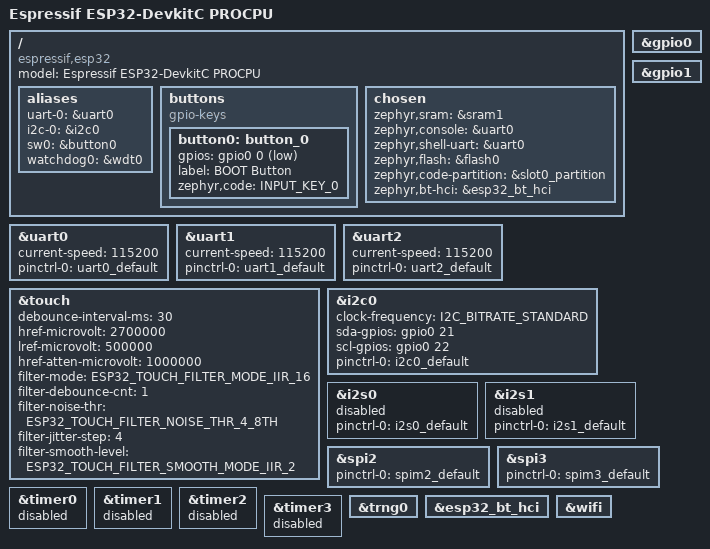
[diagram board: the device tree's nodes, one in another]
/*
 * Copyright (c) 2023-2025 Espressif Systems (Shanghai) Co., Ltd.
 *
 * SPDX-License-Identifier: Apache-2.0
 */
/dts-v1/;

#include <espressif/esp32/esp32_wrover_e_n4r8.dtsi>
#include "esp32_devkitc-pinctrl.dtsi"
#include <zephyr/dt-bindings/input/input-event-codes.h>
#include <zephyr/dt-bindings/input/esp32-touch-sensor-input.h>
#include <espressif/partitions_0x1000_amp.dtsi>

/ {
	model = "Espressif ESP32-DevkitC PROCPU";
	compatible = "espressif,esp32";

	aliases {
		uart-0 = &uart0;
		i2c-0 = &i2c0;
		sw0 = &button0;
		watchdog0 = &wdt0;
	};

	buttons {
		compatible = "gpio-keys";

		button0: button_0 {
			gpios = <&gpio0 0 (GPIO_PULL_UP | GPIO_ACTIVE_LOW)>;
			label = "BOOT Button";
			zephyr,code = <INPUT_KEY_0>;
		};
	};

	chosen {
		zephyr,sram = &sram1;
		zephyr,console = &uart0;
		zephyr,shell-uart = &uart0;
		zephyr,flash = &flash0;
		zephyr,code-partition = &slot0_partition;
		zephyr,bt-hci = &esp32_bt_hci;
	};
};

&uart0 {
	status = "okay";
	current-speed = <115200>;
	pinctrl-0 = <&uart0_default>;
	pinctrl-names = "default";
};

&uart1 {
	current-speed = <115200>;
	pinctrl-0 = <&uart1_default>;
	pinctrl-names = "default";
};

&uart2 {
	current-speed = <115200>;
	pinctrl-0 = <&uart2_default>;
	pinctrl-names = "default";
};

&gpio0 {
	status = "okay";
};

&gpio1 {
	status = "okay";
};

&touch {
	debounce-interval-ms = <30>;
	href-microvolt = <2700000>;
	lref-microvolt = <500000>;
	href-atten-microvolt = <1000000>;
	filter-mode = <ESP32_TOUCH_FILTER_MODE_IIR_16>;
	filter-debounce-cnt = <1>;
	filter-noise-thr = <ESP32_TOUCH_FILTER_NOISE_THR_4_8TH>;
	filter-jitter-step = <4>;
	filter-smooth-level = <ESP32_TOUCH_FILTER_SMOOTH_MODE_IIR_2>;
};

&i2c0 {
	status = "okay";
	clock-frequency = <I2C_BITRATE_STANDARD>;
	sda-gpios = <&gpio0 21 GPIO_OPEN_DRAIN>;
	scl-gpios = <&gpio0 22 GPIO_OPEN_DRAIN>;
	pinctrl-0 = <&i2c0_default>;
	pinctrl-names = "default";
};

&i2s0 {
	pinctrl-0 = <&i2s0_default>;
	pinctrl-names = "default";
	status = "disabled";
};

&i2s1 {
	pinctrl-0 = <&i2s1_default>;
	pinctrl-names = "default";
	status = "disabled";
};

&spi2 {
	#address-cells = <1>;
	#size-cells = <0>;
	status = "okay";
	pinctrl-0 = <&spim2_default>;
	pinctrl-names = "default";
};

&spi3 {
	#address-cells = <1>;
	#size-cells = <0>;
	status = "okay";
	pinctrl-0 = <&spim3_default>;
	pinctrl-names = "default";
};

&timer0 {
	status = "disabled";
};

&timer1 {
	status = "disabled";
};

&timer2 {
	status = "disabled";
};

&timer3 {
	status = "disabled";
};

&trng0 {
	status = "okay";
};

&esp32_bt_hci {
	status = "okay";
};

&wifi {
	status = "okay";
};
